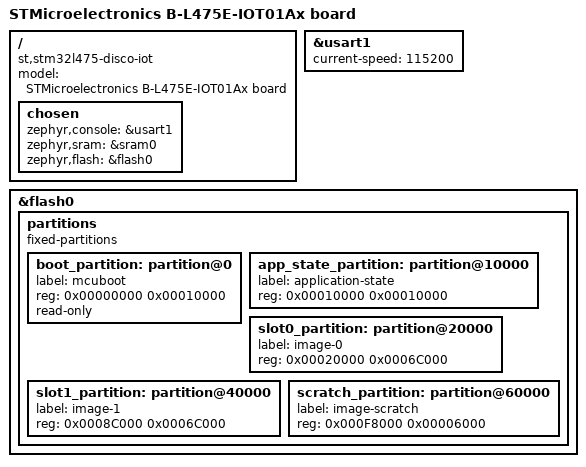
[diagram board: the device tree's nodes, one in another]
/*
 * Copyright (c) 2017 Linaro Limited
 *
 * SPDX-License-Identifier: Apache-2.0
 */

/dts-v1/;
#include <st/stm32l475.dtsi>

/ {
	model = "STMicroelectronics B-L475E-IOT01Ax board";
	compatible = "st,stm32l475-disco-iot", "st,stm32l475";

	chosen {
		zephyr,console = &usart1;
		zephyr,sram = &sram0;
		zephyr,flash = &flash0;
	};
};

&usart1 {
	current-speed = <115200>;
	status = "ok";
};
&flash0 {
	partitions {
		/*
		 * If chosen's zephyr,code-partion is unset, the image will be
		 * linked into the entire flash device.  If it points to an
		 * individual partition, the code will be linked to, and
		 * restricted to that partition.
		 */
		compatible = "fixed-partitions";
		#address-cells = <1>;
		#size-cells = <1>;

		boot_partition: partition@0 {
			label = "mcuboot";
			reg = <0x00000000 0x00010000>;
			read-only;
		};
		app_state_partition: partition@10000 {
			label = "application-state";
			reg = <0x00010000 0x00010000>;
		};
		slot0_partition: partition@20000 {
			label = "image-0";
			reg = <0x00020000 0x0006C000>;
		};
		slot1_partition: partition@40000 {
			label = "image-1";
			reg = <0x0008C000 0x0006C000>;
		};
		scratch_partition: partition@60000 {
			label = "image-scratch";
			reg = <0x000F8000 0x00006000>;
		};
	};


};
